# cc13x2_cc26x2 register map
File version: 2.1
CPU: CM4 r0p1, little endian, MPU, FPU, 3 interrupt priority bits
Registers are 32-bit, read-write, reset 0x0 unless marked. A register's access mark holds for its fields unless they carry their own. Offsets are from the block's base; [hi:lo] are bit positions.

## UART0 — Universal Asynchronous Receiver/Transmitter (UART) interface
Base 0x40001000
Same registers: UART1 0x4000B000
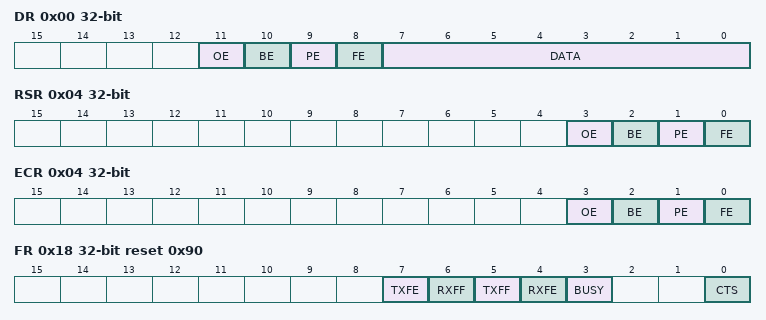
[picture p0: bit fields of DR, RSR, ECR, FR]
0x00 DR — Data or words to be transmitted: - if the FIFOs are enabled (LCRH.FEN = 1), data written to this location is pushed onto the transmit FIFO - if the FIFOs are not enabled (LCRH.FEN = 0), data is stored in the transmitter holding register (the bottom word of the transmit FIFO). he write operation initiates transmission from the UART. The data is prefixed with a start bit, appended with the appropriate parity bit (if parity is enabled), and a stop bit. he resultant word is then transmitted. or received words: - if the FIFOs are enabled (LCRH.FEN = 1), the data byte and the 4-bit status (break, frame, parity, and overrun) is pushed onto the 12-bit wide receive FIFO - if the FIFOs are not enabled (LCRH.FEN = 0), the data byte and status are stored in the receiving holding register (the bottom word of the receive FIFO). he received data byte is read by performing reads from this register along with the corresponding status information. The status information can also be read by a read of the RSR register.
  [11] OE, [10] BE, [9] PE, [8] FE, [7:0] DATA
0x04 RSR ro — Status his register is mapped to the same address as ECR register. Reads from this address are associated with RSR register and return the receive status. Writes to this address are associated with ECR register and clear the receive status flags (framing, parity, break, and overrun errors). f the status is read from this register, then the status information for break, framing and parity corresponds to the data character read from the Data Register, DR prior to reading the RSR. The status information for overrun is set immediately when an overrun condition occurs.
  [3] OE, [2] BE, [1] PE, [0] FE
0x04 ECR wo — Error Clear his register is mapped to the same address as RSR register. Reads from this address are associated with RSR register and return the receive status. Writes to this address are associated with ECR register and clear the receive status flags (framing, parity, break, and overrun errors).
  [3] OE, [2] BE, [1] PE, [0] FE
0x18 FR ro reset 0x90 — Flag eads from this register return the UART flags.
  [7] TXFE, [6] RXFF, [5] TXFF, [4] RXFE, [3] BUSY, [0] CTS
0x24 IBRD — Integer Baud-Rate Divisor f this register is modified while transmission or reception is on-going, the baud rate will not be updated until transmission or reception of the current character is complete.
  [15:0] DIVINT
0x28 FBRD — Fractional Baud-Rate Divisor f this register is modified while trasmission or reception is on-going, the baudrate will not be updated until transmission or reception of the current character is complete.
  [5:0] DIVFRAC
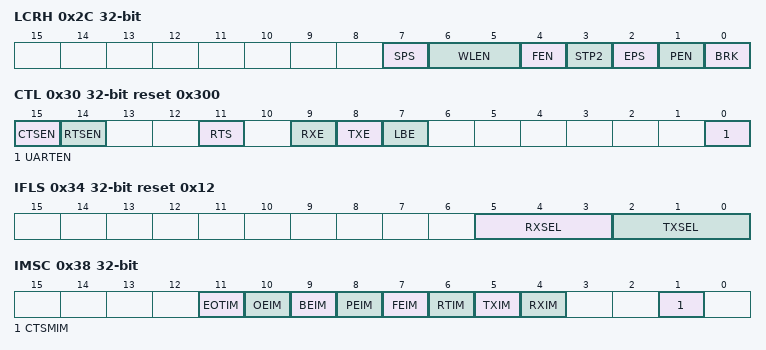
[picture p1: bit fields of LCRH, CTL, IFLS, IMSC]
0x2C LCRH — Line Control
  [7] SPS, [6:5] WLEN, [4] FEN, [3] STP2, [2] EPS, [1] PEN, [0] BRK
0x30 CTL reset 0x300 — Control
  [15] CTSEN, [14] RTSEN, [11] RTS, [9] RXE, [8] TXE, [7] LBE, [0] UARTEN
0x34 IFLS reset 0x12 — Interrupt FIFO Level Select
  [5:3] RXSEL, [2:0] TXSEL
0x38 IMSC — Interrupt Mask Set/Clear
  [11] EOTIM, [10] OEIM, [9] BEIM, [8] PEIM, [7] FEIM, [6] RTIM, [5] TXIM, [4] RXIM, [1] CTSMIM
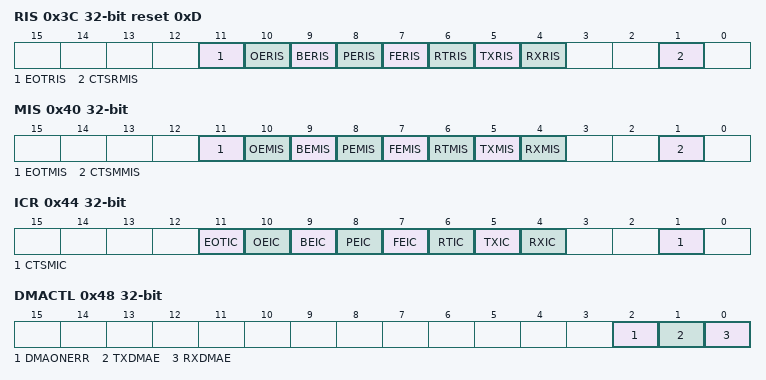
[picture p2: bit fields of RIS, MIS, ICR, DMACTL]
0x3C RIS ro reset 0xD — Raw Interrupt Status
  [11] EOTRIS, [10] OERIS, [9] BERIS, [8] PERIS, [7] FERIS, [6] RTRIS, [5] TXRIS, [4] RXRIS, [1] CTSRMIS
0x40 MIS ro — Masked Interrupt Status
  [11] EOTMIS, [10] OEMIS, [9] BEMIS, [8] PEMIS, [7] FEMIS, [6] RTMIS, [5] TXMIS, [4] RXMIS, [1] CTSMMIS
0x44 ICR wo — Interrupt Clear n a write of 1, the corresponding interrupt is cleared. A write of 0 has no effect.
  [11] EOTIC, [10] OEIC, [9] BEIC, [8] PEIC, [7] FEIC, [6] RTIC, [5] TXIC, [4] RXIC, [1] CTSMIC
0x48 DMACTL — DMA Control
  [2] DMAONERR, [1] TXDMAE, [0] RXDMAE
